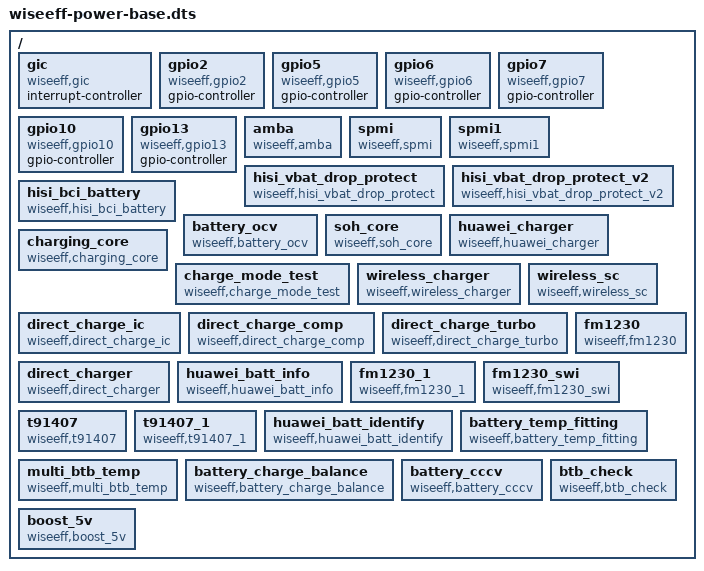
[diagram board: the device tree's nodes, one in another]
/dts-v1/;

/*
 * Synthetic, test-only base tree for `base-power-overlay.dts`.
 *
 * This is not a real board's device tree. It exists solely so the seed
 * overlay's `&label { ... }` fragments and phandle references resolve to a
 * concrete target during real `dtc`/`fdtoverlay` compilation. Every target
 * node below carries a stable `wiseeff,<label>` compatible string purely for
 * test identification; GPIO controller nodes additionally declare
 * `gpio-controller` and `#gpio-cells = <2>` so `<&gpioN pin flags>` phandle
 * cells are well-formed.
 */

/ {
	#address-cells = <1>;
	#size-cells = <1>;

	gic: gic {
		compatible = "wiseeff,gic";
		interrupt-controller;
		#interrupt-cells = <3>;
	};

	gpio2: gpio2 {
		compatible = "wiseeff,gpio2";
		gpio-controller;
		#gpio-cells = <2>;
	};

	gpio5: gpio5 {
		compatible = "wiseeff,gpio5";
		gpio-controller;
		#gpio-cells = <2>;
	};

	gpio6: gpio6 {
		compatible = "wiseeff,gpio6";
		gpio-controller;
		#gpio-cells = <2>;
	};

	gpio7: gpio7 {
		compatible = "wiseeff,gpio7";
		gpio-controller;
		#gpio-cells = <2>;
	};

	gpio10: gpio10 {
		compatible = "wiseeff,gpio10";
		gpio-controller;
		#gpio-cells = <2>;
	};

	gpio13: gpio13 {
		compatible = "wiseeff,gpio13";
		gpio-controller;
		#gpio-cells = <2>;
	};

	amba: amba {
		compatible = "wiseeff,amba";
	};

	spmi: spmi {
		compatible = "wiseeff,spmi";
	};

	spmi1: spmi1 {
		compatible = "wiseeff,spmi1";
	};

	hisi_vbat_drop_protect: hisi_vbat_drop_protect {
		compatible = "wiseeff,hisi_vbat_drop_protect";
	};

	hisi_vbat_drop_protect_v2: hisi_vbat_drop_protect_v2 {
		compatible = "wiseeff,hisi_vbat_drop_protect_v2";
	};

	hisi_bci_battery: hisi_bci_battery {
		compatible = "wiseeff,hisi_bci_battery";
	};

	battery_ocv: battery_ocv {
		compatible = "wiseeff,battery_ocv";
	};

	soh_core: soh_core {
		compatible = "wiseeff,soh_core";
	};

	huawei_charger: huawei_charger {
		compatible = "wiseeff,huawei_charger";
	};

	charging_core: charging_core {
		compatible = "wiseeff,charging_core";
	};

	charge_mode_test: charge_mode_test {
		compatible = "wiseeff,charge_mode_test";
	};

	wireless_charger: wireless_charger {
		compatible = "wiseeff,wireless_charger";
	};

	wireless_sc: wireless_sc {
		compatible = "wiseeff,wireless_sc";
	};

	direct_charge_ic: direct_charge_ic {
		compatible = "wiseeff,direct_charge_ic";
	};

	direct_charge_comp: direct_charge_comp {
		compatible = "wiseeff,direct_charge_comp";
	};

	direct_charge_turbo: direct_charge_turbo {
		compatible = "wiseeff,direct_charge_turbo";
	};

	direct_charger: direct_charger {
		compatible = "wiseeff,direct_charger";
	};

	huawei_batt_info: huawei_batt_info {
		compatible = "wiseeff,huawei_batt_info";
	};

	fm1230: fm1230 {
		compatible = "wiseeff,fm1230";
	};

	fm1230_1: fm1230_1 {
		compatible = "wiseeff,fm1230_1";
	};

	fm1230_swi: fm1230_swi {
		compatible = "wiseeff,fm1230_swi";
	};

	t91407: t91407 {
		compatible = "wiseeff,t91407";
	};

	t91407_1: t91407_1 {
		compatible = "wiseeff,t91407_1";
	};

	huawei_batt_identify: huawei_batt_identify {
		compatible = "wiseeff,huawei_batt_identify";
	};

	battery_temp_fitting: battery_temp_fitting {
		compatible = "wiseeff,battery_temp_fitting";
	};

	multi_btb_temp: multi_btb_temp {
		compatible = "wiseeff,multi_btb_temp";
	};

	battery_charge_balance: battery_charge_balance {
		compatible = "wiseeff,battery_charge_balance";
	};

	battery_cccv: battery_cccv {
		compatible = "wiseeff,battery_cccv";
	};

	btb_check: btb_check {
		compatible = "wiseeff,btb_check";
	};

	boost_5v: boost_5v {
		compatible = "wiseeff,boost_5v";
	};
};
